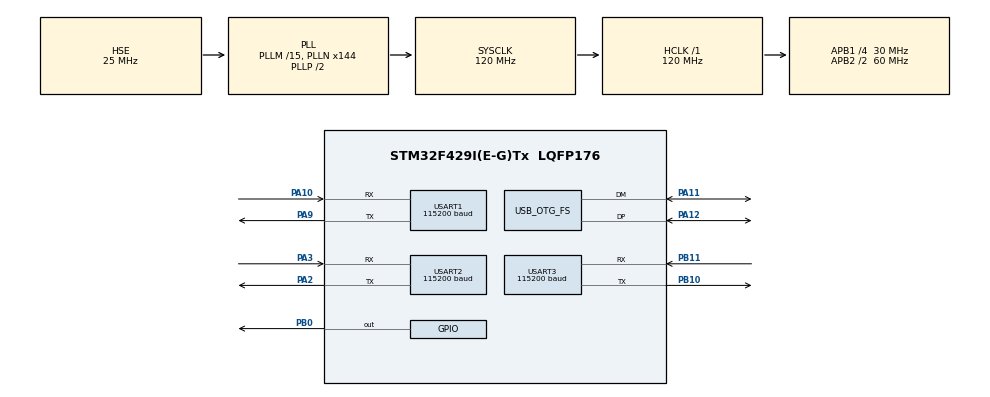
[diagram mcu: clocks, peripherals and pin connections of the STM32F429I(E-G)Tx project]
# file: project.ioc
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Dma.Request0=USART1_TX
Dma.Request1=USART1_RX
Dma.Request2=USART2_TX
Dma.Request3=USART2_RX
Dma.USART1_RX.1.Direction=DMA_PERIPH_TO_MEMORY
Dma.USART1_RX.1.FIFOMode=DMA_FIFOMODE_DISABLE
Dma.USART1_RX.1.Instance=DMA2_Stream2
Dma.USART1_RX.1.MemDataAlignment=DMA_MDATAALIGN_BYTE
Dma.USART1_RX.1.MemInc=DMA_MINC_ENABLE
Dma.USART1_RX.1.Mode=DMA_NORMAL
Dma.USART1_RX.1.PeriphDataAlignment=DMA_PDATAALIGN_BYTE
Dma.USART1_RX.1.PeriphInc=DMA_PINC_DISABLE
Dma.USART1_RX.1.Priority=DMA_PRIORITY_MEDIUM
Dma.USART1_TX.0.Direction=DMA_MEMORY_TO_PERIPH
Dma.USART1_TX.0.FIFOMode=DMA_FIFOMODE_DISABLE
Dma.USART1_TX.0.Instance=DMA2_Stream7
Dma.USART1_TX.0.MemDataAlignment=DMA_MDATAALIGN_BYTE
Dma.USART1_TX.0.MemInc=DMA_MINC_ENABLE
Dma.USART1_TX.0.Mode=DMA_NORMAL
Dma.USART1_TX.0.PeriphDataAlignment=DMA_PDATAALIGN_BYTE
Dma.USART1_TX.0.PeriphInc=DMA_PINC_DISABLE
Dma.USART1_TX.0.Priority=DMA_PRIORITY_MEDIUM
Dma.USART2_RX.3.Direction=DMA_PERIPH_TO_MEMORY
Dma.USART2_RX.3.FIFOMode=DMA_FIFOMODE_DISABLE
Dma.USART2_RX.3.Instance=DMA1_Stream5
Dma.USART2_RX.3.MemDataAlignment=DMA_MDATAALIGN_BYTE
Dma.USART2_RX.3.MemInc=DMA_MINC_ENABLE
Dma.USART2_RX.3.Mode=DMA_NORMAL
Dma.USART2_RX.3.PeriphDataAlignment=DMA_PDATAALIGN_BYTE
Dma.USART2_RX.3.PeriphInc=DMA_PINC_DISABLE
Dma.USART2_RX.3.Priority=DMA_PRIORITY_LOW
Dma.USART2_TX.2.Direction=DMA_MEMORY_TO_PERIPH
Dma.USART2_TX.2.FIFOMode=DMA_FIFOMODE_DISABLE
Dma.USART2_TX.2.Instance=DMA1_Stream6
Dma.USART2_TX.2.MemDataAlignment=DMA_MDATAALIGN_BYTE
Dma.USART2_TX.2.MemInc=DMA_MINC_ENABLE
Dma.USART2_TX.2.Mode=DMA_NORMAL
Dma.USART2_TX.2.PeriphDataAlignment=DMA_PDATAALIGN_BYTE
Dma.USART2_TX.2.PeriphInc=DMA_PINC_DISABLE
Dma.USART2_TX.2.Priority=DMA_PRIORITY_LOW
Mcu.Family=STM32F4
Mcu.Name=STM32F429I(E-G)Tx
Mcu.Package=LQFP176
NVIC.DMA1_Stream5_IRQn=true\:0\:0\:false\:false\:true\:false\:true\:true
NVIC.DMA1_Stream6_IRQn=true\:0\:0\:false\:false\:true\:false\:true\:true
NVIC.DMA2_Stream2_IRQn=true\:0\:0\:false\:false\:true\:false\:true\:true
NVIC.DMA2_Stream7_IRQn=true\:0\:0\:false\:false\:true\:false\:true\:true
NVIC.OTG_FS_IRQn=true\:0\:0\:false\:false\:true\:true\:true\:true
NVIC.PriorityGroup=NVIC_PRIORITYGROUP_4
NVIC.USART1_IRQn=true\:5\:0\:true\:false\:true\:true\:true\:true
NVIC.USART2_IRQn=true\:5\:0\:true\:false\:true\:true\:true\:true
NVIC.USART3_IRQn=true\:5\:0\:true\:false\:true\:true\:true\:true
PA10.GPIO_PuPd=GPIO_PULLUP
PA10.Mode=Asynchronous
PA10.Signal=USART1_RX
PA11.Mode=Device_Only
PA11.Signal=USB_OTG_FS_DM
PA12.Mode=Device_Only
PA12.Signal=USB_OTG_FS_DP
PA13.Mode=Serial_Wire
PA13.Signal=SYS_JTMS-SWDIO
PA14.Mode=Serial_Wire
PA14.Signal=SYS_JTCK-SWCLK
PA2.GPIO_PuPd=GPIO_PULLUP
PA2.Mode=Asynchronous
PA2.Signal=USART2_TX
PA3.GPIO_PuPd=GPIO_PULLUP
PA3.Mode=Asynchronous
PA3.Signal=USART2_RX
PA9.GPIO_PuPd=GPIO_PULLUP
PA9.Mode=Asynchronous
PA9.Signal=USART1_TX
PB0.GPIO_Speed=GPIO_SPEED_FREQ_HIGH
PB0.PinState=GPIO_PIN_SET
PB0.Signal=GPIO_Output
PB10.GPIO_PuPd=GPIO_PULLUP
PB10.Mode=Asynchronous
PB10.Signal=USART3_TX
PB11.GPIO_PuPd=GPIO_PULLUP
PB11.Mode=Asynchronous
PB11.Signal=USART3_RX
PC14/OSC32_IN.Mode=LSE-External-Oscillator
PC14/OSC32_IN.Signal=RCC_OSC32_IN
PC15/OSC32_OUT.Mode=LSE-External-Oscillator
PC15/OSC32_OUT.Signal=RCC_OSC32_OUT
PH0/OSC_IN.Mode=HSE-External-Oscillator
PH0/OSC_IN.Signal=RCC_OSC_IN
PH1/OSC_OUT.Mode=HSE-External-Oscillator
PH1/OSC_OUT.Signal=RCC_OSC_OUT
ProjectManager.HeapSize=0x200
ProjectManager.StackSize=0x400
ProjectManager.TargetToolchain=CMake
RCC.48MHZClocksFreq_Value=48000000
RCC.AHBFreq_Value=120000000
RCC.APB1CLKDivider=RCC_HCLK_DIV4
RCC.APB1Freq_Value=30000000
RCC.APB1TimFreq_Value=60000000
RCC.APB2CLKDivider=RCC_HCLK_DIV2
RCC.APB2Freq_Value=60000000
RCC.APB2TimFreq_Value=120000000
RCC.CortexFreq_Value=120000000
RCC.FLatency=FLASH_LATENCY_3
RCC.HCLKFreq_Value=120000000
RCC.HSE_VALUE=25000000
RCC.HSI_VALUE=16000000
RCC.PLLM=15
RCC.PLLN=144
RCC.PLLQ=5
RCC.PWREXT_OverDrive=PWREXT_OverDrive_ACTIVATED
RCC.PWR_Regulator_Voltage_Scale=PWR_REGULATOR_VOLTAGE_SCALE1
RCC.SYSCLKFreq_VALUE=120000000
RCC.SYSCLKSource=RCC_SYSCLKSOURCE_PLLCLK
RCC.VCOOutputFreq_Value=240000000
USART1.BaudRate=115200
USART1.Mode=MODE_TX_RX
USART1.OverSampling=UART_OVERSAMPLING_16
USART1.Parity=PARITY_NONE
USART1.StopBits=STOPBITS_1
USART1.VirtualMode=VM_ASYNC
USART1.WordLength=WORDLENGTH_8B
USART2.BaudRate=115200
USART2.Mode=MODE_TX_RX
USART2.OverSampling=UART_OVERSAMPLING_16
USART2.Parity=PARITY_NONE
USART2.StopBits=STOPBITS_1
USART2.VirtualMode=VM_ASYNC
USART2.WordLength=WORDLENGTH_8B
USART3.BaudRate=115200
USART3.Mode=MODE_TX_RX
USART3.OverSampling=UART_OVERSAMPLING_16
USART3.Parity=PARITY_NONE
USART3.StopBits=STOPBITS_1
USART3.VirtualMode=VM_ASYNC
USART3.WordLength=WORDLENGTH_8B
USB_DEVICE.APP_RX_DATA_SIZE-CDC_FS=2048
USB_DEVICE.APP_TX_DATA_SIZE-CDC_FS=2048
USB_DEVICE.CLASS_NAME_FS=CDC
USB_DEVICE.CONFIGURATION_STRING_CDC_FS=CDC Config
USB_DEVICE.INTERFACE_STRING_CDC_FS=CDC Interface
USB_DEVICE.LANGID_STRING-CDC_FS=1033
USB_DEVICE.MANUFACTURER_STRING-CDC_FS=STMicroelectronics
USB_DEVICE.PID_CDC_FS=22336
USB_DEVICE.PRODUCT_STRING_CDC_FS=STM32 Virtual ComPort
USB_DEVICE.USBD_DEBUG_LEVEL-CDC_FS=0
USB_DEVICE.USBD_MAX_NUM_CONFIGURATION-CDC_FS=1
USB_DEVICE.USBD_MAX_NUM_INTERFACES-CDC_FS=1
USB_DEVICE.USBD_MAX_STR_DESC_SIZ-CDC_FS=512
USB_DEVICE.USBD_SELF_POWERED-CDC_FS=1
USB_DEVICE.VID-CDC_FS=1155
USB_DEVICE.VirtualMode-CDC_FS=Cdc
USB_DEVICE.VirtualModeFS=Cdc_FS
USB_OTG_FS.Sof_enable=DISABLE
USB_OTG_FS.VirtualMode=Device_Only
USB_OTG_FS.low_power_enable=DISABLE
USB_OTG_FS.lpm_enable=DISABLE
USB_OTG_FS.vbus_sensing_enable=DISABLE
VP_USB_DEVICE_VS_USB_DEVICE_CDC_FS.Mode=CDC_FS
board=custom

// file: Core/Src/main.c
/* USER CODE BEGIN Header */
/**
  ******************************************************************************
  * @file           : main.c
  * @brief          : Main program body
  ******************************************************************************
  * @attention
  *
  * Copyright (c) 2024 STMicroelectronics.
  * All rights reserved.
  *
  * This software is licensed under terms that can be found in the LICENSE file
  * in the root directory of this software component.
  * If no LICENSE file comes with this software, it is provided AS-IS.
  *
  ******************************************************************************
  */
/* USER CODE END Header */
#include "main.h"
#include "dma.h"
#include "usart.h"
#include "usb_device.h"
#include "gpio.h"

/* USER CODE BEGIN Includes */
#include "app_main.h"
/* USER CODE END Includes */

void SystemClock_Config(void);

int main(void)
{

  /* MCU Configuration--------------------------------------------------------*/

  /* Reset of all peripherals, Initializes the Flash interface and the Systick. */
  HAL_Init();

  /* Configure the system clock */
  SystemClock_Config();

  /* Initialize all configured peripherals */
  MX_GPIO_Init();
  MX_DMA_Init();
  MX_USART1_UART_Init();
  MX_USART2_UART_Init();
  MX_USART3_UART_Init();
  MX_USB_DEVICE_Init();
  /* USER CODE BEGIN 2 */
#if (SYSTEM_SUPPORT_OS == 1)
    xTaskCreate(app_main_thread, "app_main_thread", APP_MAIN_TASK_STACK_SIZE, NULL, APP_MAIN_TASK_PRIORITY, &app_main_thread_handle);
    vTaskStartScheduler();
#else
    app_main();
#endif
  /* USER CODE END 2 */

  /* Infinite loop */
  while (1)
  {

  }
}

void SystemClock_Config(void)
{
  RCC_OscInitTypeDef RCC_OscInitStruct = {0};
  RCC_ClkInitTypeDef RCC_ClkInitStruct = {0};

  /** Configure the main internal regulator output voltage
  */
  __HAL_RCC_PWR_CLK_ENABLE();
  __HAL_PWR_VOLTAGESCALING_CONFIG(PWR_REGULATOR_VOLTAGE_SCALE1);

  /** Initializes the RCC Oscillators according to the specified parameters
  * in the RCC_OscInitTypeDef structure.
  */
  RCC_OscInitStruct.OscillatorType = RCC_OSCILLATORTYPE_HSE;
  RCC_OscInitStruct.HSEState = RCC_HSE_ON;
  RCC_OscInitStruct.PLL.PLLState = RCC_PLL_ON;
  RCC_OscInitStruct.PLL.PLLSource = RCC_PLLSOURCE_HSE;
  RCC_OscInitStruct.PLL.PLLM = 15;
  RCC_OscInitStruct.PLL.PLLN = 144;
  RCC_OscInitStruct.PLL.PLLP = RCC_PLLP_DIV2;
  RCC_OscInitStruct.PLL.PLLQ = 5;
  if (HAL_RCC_OscConfig(&RCC_OscInitStruct) != HAL_OK)
  {
    Error_Handler();
  }

  /** Activate the Over-Drive mode
  */
  if (HAL_PWREx_EnableOverDrive() != HAL_OK)
  {
    Error_Handler();
  }

  /** Initializes the CPU, AHB and APB buses clocks
  */
  RCC_ClkInitStruct.ClockType = RCC_CLOCKTYPE_HCLK|RCC_CLOCKTYPE_SYSCLK
                              |RCC_CLOCKTYPE_PCLK1|RCC_CLOCKTYPE_PCLK2;
  RCC_ClkInitStruct.SYSCLKSource = RCC_SYSCLKSOURCE_PLLCLK;
  RCC_ClkInitStruct.AHBCLKDivider = RCC_SYSCLK_DIV1;
  RCC_ClkInitStruct.APB1CLKDivider = RCC_HCLK_DIV4;
  RCC_ClkInitStruct.APB2CLKDivider = RCC_HCLK_DIV2;

  if (HAL_RCC_ClockConfig(&RCC_ClkInitStruct, FLASH_LATENCY_3) != HAL_OK)
  {
    Error_Handler();
  }
}

void Error_Handler(void)
{
  __disable_irq();
  while (1)
  {
  }
}
